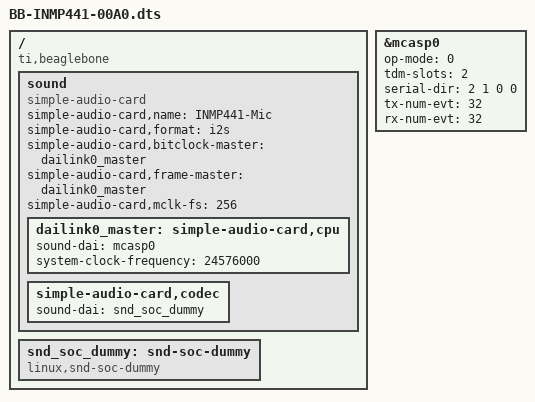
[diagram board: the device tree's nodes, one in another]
/dts-v1/;
/plugin/;

/ {
    compatible = "ti,beaglebone", "ti,beaglebone-black";

    fragment@0 {
        target = <&mcasp0>;
        __overlay__ {
            status = "okay";
            #sound-dai-cells = <0>;
            op-mode = <0>;
            tdm-slots = <2>;
            /* Add a TX (Transmit) channel to trick the clocks */
            /* 2 = RX (Mic data in), 1 = TX (Dummy data out) */
            serial-dir = < 2 1 0 0 >;
            tx-num-evt = <32>;
            rx-num-evt = <32>;
        };
    };

    fragment@1 {
        target-path = "/";
        __overlay__ {
            sound {
                compatible = "simple-audio-card";
                simple-audio-card,name = "INMP441-Mic";
                simple-audio-card,format = "i2s";

                simple-audio-card,bitclock-master = <&dailink0_master>;
                simple-audio-card,frame-master = <&dailink0_master>;
                simple-audio-card,mclk-fs = <256>;

                dailink0_master: simple-audio-card,cpu {
                    sound-dai = <&mcasp0>;
                    system-clock-frequency = <24576000>;
                };

                simple-audio-card,codec {
                    sound-dai = <&snd_soc_dummy>;
                };
            };

            /* Use a generic codec that supports playback AND recording */
            snd_soc_dummy: snd-soc-dummy {
                compatible = "linux,snd-soc-dummy";
                #sound-dai-cells = <0>;
            };
        };
    };
};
